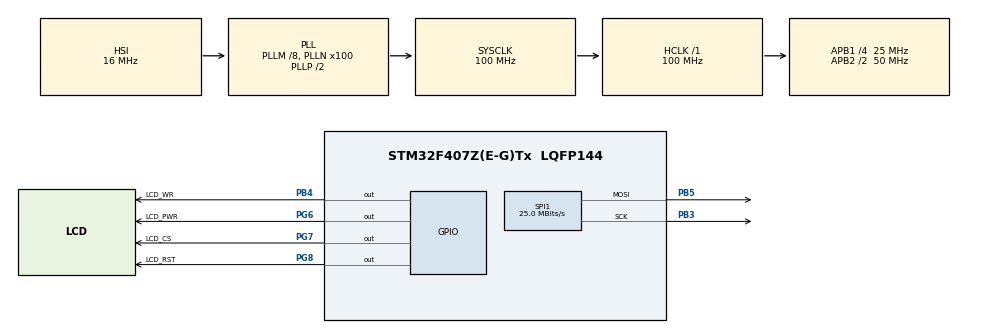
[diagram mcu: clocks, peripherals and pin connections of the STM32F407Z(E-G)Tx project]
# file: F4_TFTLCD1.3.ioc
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Mcu.Family=STM32F4
Mcu.Name=STM32F407Z(E-G)Tx
Mcu.Package=LQFP144
NVIC.PriorityGroup=NVIC_PRIORITYGROUP_4
PB3.Mode=TX_Only_Simplex_Unidirect_Master
PB3.Signal=SPI1_SCK
PB4.GPIO_Label=LCD_WR
PB4.Signal=GPIO_Output
PB5.Mode=TX_Only_Simplex_Unidirect_Master
PB5.Signal=SPI1_MOSI
PG6.GPIO_Label=LCD_PWR
PG6.Signal=GPIO_Output
PG7.GPIO_Label=LCD_CS
PG7.Signal=GPIO_Output
PG8.GPIO_Label=LCD_RST
PG8.Signal=GPIO_Output
PH0-OSC_IN.Mode=HSE-External-Oscillator
PH0-OSC_IN.Signal=RCC_OSC_IN
PH1-OSC_OUT.Mode=HSE-External-Oscillator
PH1-OSC_OUT.Signal=RCC_OSC_OUT
ProjectManager.HeapSize=0x200
ProjectManager.StackSize=0x400
ProjectManager.TargetToolchain=MDK-ARM V5.27
RCC.48MHZClocksFreq_Value=50000000
RCC.AHBFreq_Value=100000000
RCC.APB1CLKDivider=RCC_HCLK_DIV4
RCC.APB1Freq_Value=25000000
RCC.APB1TimFreq_Value=50000000
RCC.APB2CLKDivider=RCC_HCLK_DIV2
RCC.APB2Freq_Value=50000000
RCC.APB2TimFreq_Value=100000000
RCC.CortexFreq_Value=100000000
RCC.HCLKFreq_Value=100000000
RCC.HSE_VALUE=25000000
RCC.HSI_VALUE=16000000
RCC.LSE_VALUE=32768
RCC.PLLM=8
RCC.PLLN=100
RCC.SYSCLKFreq_VALUE=100000000
RCC.SYSCLKSource=RCC_SYSCLKSOURCE_PLLCLK
RCC.VCOOutputFreq_Value=200000000
SPI1.CLKPhase=SPI_PHASE_2EDGE
SPI1.CLKPolarity=SPI_POLARITY_HIGH
SPI1.CalculateBaudRate=25.0 MBits/s
SPI1.Direction=SPI_DIRECTION_2LINES
SPI1.Mode=SPI_MODE_MASTER
SPI1.VirtualType=VM_MASTER
board=custom

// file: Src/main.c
/* USER CODE BEGIN Header */
/**
  ******************************************************************************
  * @file           : main.c
  * @brief          : Main program body
  ******************************************************************************
  * @attention
  *
  * <h2><center>&copy; Copyright (c) 2020 STMicroelectronics.
  * All rights reserved.</center></h2>
  *
  * This software component is licensed by ST under BSD 3-Clause license,
  * the "License"; You may not use this file except in compliance with the
  * License. You may obtain a copy of the License at:
  *                        opensource.org/licenses/BSD-3-Clause
  *
  ******************************************************************************
  */
/* USER CODE END Header */

#include "main.h"
#include "spi.h"
#include "gpio.h"

void SystemClock_Config(void);

int main(void)
{

  /* MCU Configuration--------------------------------------------------------*/

  /* Reset of all peripherals, Initializes the Flash interface and the Systick. */
  HAL_Init();

  /* Configure the system clock */
  SystemClock_Config();

  /* Initialize all configured peripherals */
  MX_GPIO_Init();
  MX_SPI1_Init();
  /* USER CODE BEGIN 2 */
  //LCD初始化
  LCD_Init();

  /* USER CODE END 2 */

  /* Infinite loop */
  while (1)
  {
	blink_expression();
  }
}

void SystemClock_Config(void)
{
  RCC_OscInitTypeDef RCC_OscInitStruct = {0};
  RCC_ClkInitTypeDef RCC_ClkInitStruct = {0};

  /** Configure the main internal regulator output voltage
  */
  __HAL_RCC_PWR_CLK_ENABLE();
  __HAL_PWR_VOLTAGESCALING_CONFIG(PWR_REGULATOR_VOLTAGE_SCALE1);
  /** Initializes the CPU, AHB and APB busses clocks
  */
  RCC_OscInitStruct.OscillatorType = RCC_OSCILLATORTYPE_HSI;
  RCC_OscInitStruct.HSIState = RCC_HSI_ON;
  RCC_OscInitStruct.HSICalibrationValue = RCC_HSICALIBRATION_DEFAULT;
  RCC_OscInitStruct.PLL.PLLState = RCC_PLL_ON;
  RCC_OscInitStruct.PLL.PLLSource = RCC_PLLSOURCE_HSI;
  RCC_OscInitStruct.PLL.PLLM = 8;
  RCC_OscInitStruct.PLL.PLLN = 100;
  RCC_OscInitStruct.PLL.PLLP = RCC_PLLP_DIV2;
  RCC_OscInitStruct.PLL.PLLQ = 4;
  if (HAL_RCC_OscConfig(&RCC_OscInitStruct) != HAL_OK)
  {
    Error_Handler();
  }
  /** Initializes the CPU, AHB and APB busses clocks
  */
  RCC_ClkInitStruct.ClockType = RCC_CLOCKTYPE_HCLK|RCC_CLOCKTYPE_SYSCLK
                              |RCC_CLOCKTYPE_PCLK1|RCC_CLOCKTYPE_PCLK2;
  RCC_ClkInitStruct.SYSCLKSource = RCC_SYSCLKSOURCE_PLLCLK;
  RCC_ClkInitStruct.AHBCLKDivider = RCC_SYSCLK_DIV1;
  RCC_ClkInitStruct.APB1CLKDivider = RCC_HCLK_DIV4;
  RCC_ClkInitStruct.APB2CLKDivider = RCC_HCLK_DIV2;

  if (HAL_RCC_ClockConfig(&RCC_ClkInitStruct, FLASH_LATENCY_3) != HAL_OK)
  {
    Error_Handler();
  }
}

void Error_Handler(void)
{
}

/************************ (C) COPYRIGHT STMicroelectronics *****END OF FILE****/
